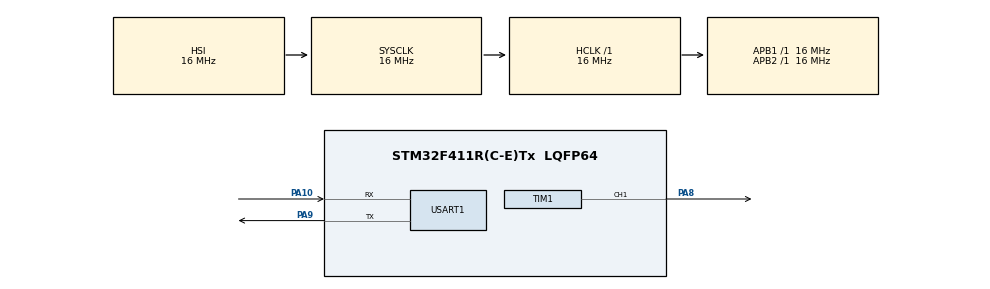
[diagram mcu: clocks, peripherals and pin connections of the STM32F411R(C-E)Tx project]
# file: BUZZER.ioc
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Mcu.Family=STM32F4
Mcu.Name=STM32F411R(C-E)Tx
Mcu.Package=LQFP64
NVIC.PriorityGroup=NVIC_PRIORITYGROUP_4
NVIC.USART1_IRQn=true\:0\:0\:false\:false\:true\:true\:true\:true
PA10.Mode=Asynchronous
PA10.Signal=USART1_RX
PA8.Signal=S_TIM1_CH1
PA9.Mode=Asynchronous
PA9.Signal=USART1_TX
ProjectManager.HeapSize=0x200
ProjectManager.StackSize=0x400
ProjectManager.TargetToolchain=STM32CubeIDE
RCC.AHBFreq_Value=16000000
RCC.APB1Freq_Value=16000000
RCC.APB2Freq_Value=16000000
RCC.CortexFreq_Value=16000000
RCC.HSE_VALUE=25000000
RCC.HSI_VALUE=16000000
RCC.LSE_VALUE=32768
RCC.SYSCLKFreq_VALUE=16000000
RCC.VCOOutputFreq_Value=192000000
SH.S_TIM1_CH1.0=TIM1_CH1,PWM Generation1 CH1
TIM1.Channel-PWM\ Generation1\ CH1=TIM_CHANNEL_1
TIM1.Period=999
TIM1.Prescaler=15
TIM1.Pulse-PWM\ Generation1\ CH1=499
USART1.VirtualMode=VM_ASYNC
VP_TIM1_VS_ClockSourceINT.Mode=Internal
board=custom

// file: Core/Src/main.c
/* USER CODE BEGIN Header */
/**
  ******************************************************************************
  * @file           : main.c
  * @brief          : Main program body
  ******************************************************************************
  * @attention
  *
  * Copyright (c) 2023 STMicroelectronics.
  * All rights reserved.
  *
  * This software is licensed under terms that can be found in the LICENSE file
  * in the root directory of this software component.
  * If no LICENSE file comes with this software, it is provided AS-IS.
  *
  ******************************************************************************
  */
/* USER CODE END Header */
#include "main.h"

/* USER CODE BEGIN Includes */
#include "uart.h";
/* USER CODE END Includes */

TIM_HandleTypeDef htim1;

UART_HandleTypeDef huart1;

void SystemClock_Config(void);
static void MX_GPIO_Init(void);
static void MX_USART1_UART_Init(void);
static void MX_TIM1_Init(void);

/* USER CODE BEGIN 0 */
int soundLut[]={131,147,165,175,196,220,247,262}; // 음계 주파수 테이블
void setSound(int freq)  // 소리 함수
{
	htim1.Instance->ARR=1000000/freq-1;  // 주파수 조정
	htim1.Instance->CCR1=htim1.Instance->CNT/2;  //주파수 조정으로 인한 듀티비 재조정
}

/* USER CODE END 0 */

int main(void)
{

  /* MCU Configuration--------------------------------------------------------*/

  /* Reset of all peripherals, Initializes the Flash interface and the Systick. */
  HAL_Init();

  /* Configure the system clock */
  SystemClock_Config();

  /* Initialize all configured peripherals */
  MX_GPIO_Init();
  MX_USART1_UART_Init();
  MX_TIM1_Init();
  /* USER CODE BEGIN 2 */
  HAL_TIM_PWM_Start(&htim1, TIM_CHANNEL_1);
  initUart();

  /* USER CODE END 2 */

  /* Infinite loop */
  while (1)
  {

    /* USER CODE BEGIN 3 */
  		char ch =getChar();

  		switch(ch)
  		{
  			case 'a':
  				setSound(soundLut[0]);
  				HAL_Delay(300);
  				break;
  			case 's':
					setSound(soundLut[1]);
  				HAL_Delay(300);
					break;
  			case 'd':
					setSound(soundLut[2]);
  				HAL_Delay(300);
					break;
  			case 'f':
					setSound(soundLut[3]);
  				HAL_Delay(300);
					break;
  			case 'g':
					setSound(soundLut[4]);
  				HAL_Delay(300);
					break;
  			case 'h':
					setSound(soundLut[5]);
  				HAL_Delay(300);
					break;
  			case 'j':
					setSound(soundLut[6]);
  				HAL_Delay(300);
					break;
  			case 'k':
					setSound(soundLut[7]);
  				HAL_Delay(300);
					break;
  		}

  }
  /* USER CODE END 3 */
}

void SystemClock_Config(void)
{
  RCC_OscInitTypeDef RCC_OscInitStruct = {0};
  RCC_ClkInitTypeDef RCC_ClkInitStruct = {0};

  /** Configure the main internal regulator output voltage
  */
  __HAL_RCC_PWR_CLK_ENABLE();
  __HAL_PWR_VOLTAGESCALING_CONFIG(PWR_REGULATOR_VOLTAGE_SCALE1);

  /** Initializes the RCC Oscillators according to the specified parameters
  * in the RCC_OscInitTypeDef structure.
  */
  RCC_OscInitStruct.OscillatorType = RCC_OSCILLATORTYPE_HSI;
  RCC_OscInitStruct.HSIState = RCC_HSI_ON;
  RCC_OscInitStruct.HSICalibrationValue = RCC_HSICALIBRATION_DEFAULT;
  RCC_OscInitStruct.PLL.PLLState = RCC_PLL_NONE;
  if (HAL_RCC_OscConfig(&RCC_OscInitStruct) != HAL_OK)
  {
    Error_Handler();
  }

  /** Initializes the CPU, AHB and APB buses clocks
  */
  RCC_ClkInitStruct.ClockType = RCC_CLOCKTYPE_HCLK|RCC_CLOCKTYPE_SYSCLK
                              |RCC_CLOCKTYPE_PCLK1|RCC_CLOCKTYPE_PCLK2;
  RCC_ClkInitStruct.SYSCLKSource = RCC_SYSCLKSOURCE_HSI;
  RCC_ClkInitStruct.AHBCLKDivider = RCC_SYSCLK_DIV1;
  RCC_ClkInitStruct.APB1CLKDivider = RCC_HCLK_DIV1;
  RCC_ClkInitStruct.APB2CLKDivider = RCC_HCLK_DIV1;

  if (HAL_RCC_ClockConfig(&RCC_ClkInitStruct, FLASH_LATENCY_0) != HAL_OK)
  {
    Error_Handler();
  }
}

static void MX_TIM1_Init(void)
{

  TIM_ClockConfigTypeDef sClockSourceConfig = {0};
  TIM_MasterConfigTypeDef sMasterConfig = {0};
  TIM_OC_InitTypeDef sConfigOC = {0};
  TIM_BreakDeadTimeConfigTypeDef sBreakDeadTimeConfig = {0};

  htim1.Instance = TIM1;
  htim1.Init.Prescaler = 15;
  htim1.Init.CounterMode = TIM_COUNTERMODE_UP;
  htim1.Init.Period = 999;
  htim1.Init.ClockDivision = TIM_CLOCKDIVISION_DIV1;
  htim1.Init.RepetitionCounter = 0;
  htim1.Init.AutoReloadPreload = TIM_AUTORELOAD_PRELOAD_DISABLE;
  if (HAL_TIM_Base_Init(&htim1) != HAL_OK)
  {
    Error_Handler();
  }
  sClockSourceConfig.ClockSource = TIM_CLOCKSOURCE_INTERNAL;
  if (HAL_TIM_ConfigClockSource(&htim1, &sClockSourceConfig) != HAL_OK)
  {
    Error_Handler();
  }
  if (HAL_TIM_PWM_Init(&htim1) != HAL_OK)
  {
    Error_Handler();
  }
  sMasterConfig.MasterOutputTrigger = TIM_TRGO_RESET;
  sMasterConfig.MasterSlaveMode = TIM_MASTERSLAVEMODE_DISABLE;
  if (HAL_TIMEx_MasterConfigSynchronization(&htim1, &sMasterConfig) != HAL_OK)
  {
    Error_Handler();
  }
  sConfigOC.OCMode = TIM_OCMODE_PWM1;
  sConfigOC.Pulse = 499;
  sConfigOC.OCPolarity = TIM_OCPOLARITY_HIGH;
  sConfigOC.OCNPolarity = TIM_OCNPOLARITY_HIGH;
  sConfigOC.OCFastMode = TIM_OCFAST_DISABLE;
  sConfigOC.OCIdleState = TIM_OCIDLESTATE_RESET;
  sConfigOC.OCNIdleState = TIM_OCNIDLESTATE_RESET;
  if (HAL_TIM_PWM_ConfigChannel(&htim1, &sConfigOC, TIM_CHANNEL_1) != HAL_OK)
  {
    Error_Handler();
  }
  sBreakDeadTimeConfig.OffStateRunMode = TIM_OSSR_DISABLE;
  sBreakDeadTimeConfig.OffStateIDLEMode = TIM_OSSI_DISABLE;
  sBreakDeadTimeConfig.LockLevel = TIM_LOCKLEVEL_OFF;
  sBreakDeadTimeConfig.DeadTime = 0;
  sBreakDeadTimeConfig.BreakState = TIM_BREAK_DISABLE;
  sBreakDeadTimeConfig.BreakPolarity = TIM_BREAKPOLARITY_HIGH;
  sBreakDeadTimeConfig.AutomaticOutput = TIM_AUTOMATICOUTPUT_DISABLE;
  if (HAL_TIMEx_ConfigBreakDeadTime(&htim1, &sBreakDeadTimeConfig) != HAL_OK)
  {
    Error_Handler();
  }
  HAL_TIM_MspPostInit(&htim1);

}

static void MX_USART1_UART_Init(void)
{

  huart1.Instance = USART1;
  huart1.Init.BaudRate = 115200;
  huart1.Init.WordLength = UART_WORDLENGTH_8B;
  huart1.Init.StopBits = UART_STOPBITS_1;
  huart1.Init.Parity = UART_PARITY_NONE;
  huart1.Init.Mode = UART_MODE_TX_RX;
  huart1.Init.HwFlowCtl = UART_HWCONTROL_NONE;
  huart1.Init.OverSampling = UART_OVERSAMPLING_16;
  if (HAL_UART_Init(&huart1) != HAL_OK)
  {
    Error_Handler();
  }

}

static void MX_GPIO_Init(void)
{

  /* GPIO Ports Clock Enable */
  __HAL_RCC_GPIOA_CLK_ENABLE();

}

void Error_Handler(void)
{
  __disable_irq();
  while (1)
  {
  }
}
